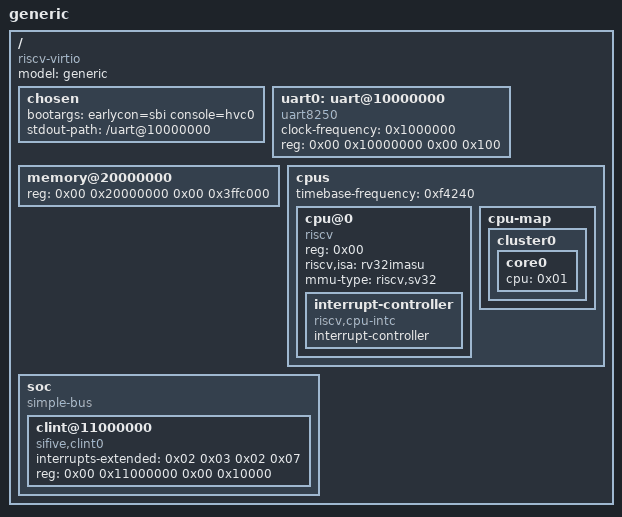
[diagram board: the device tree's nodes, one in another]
/dts-v1/;

/ {
	#address-cells = <0x2>;
	#size-cells = <0x2>;
	compatible = "riscv-virtio";
	model = "generic";

	chosen {
			bootargs = "earlycon=sbi console=hvc0";
			stdout-path = "/uart@10000000";
	};

	uart0: uart@10000000 {
		clock-frequency = <0x1000000>;
		reg = <0x00 0x10000000 0x00 0x100>;
		compatible = "uart8250";
	};

	memory@20000000 {
		device_type = "memory";
		reg = <0x00 0x20000000 0x00 0x3ffc000>;
	};

	cpus {
		#address-cells = <0x01>;
		#size-cells = <0x00>;
		timebase-frequency = <0xf4240>;

		cpu@0 {
			device_type = "cpu";
			reg = <0x00>;
			status = "okay";
			compatible = "riscv";
			riscv,isa = "rv32imasu";
			mmu-type = "riscv,sv32";

			interrupt-controller {
				#interrupt-cells = <0x01>;
				interrupt-controller;
				compatible = "riscv,cpu-intc";
				phandle = <0x02>;
			};
		};

		cpu-map {
			cluster0 {
				core0 {
					cpu = <0x01>;
				};
			};
		};
	};

	soc {
		#address-cells = <0x2>;
		#size-cells = <0x2>;
		compatible = "simple-bus";
		ranges;

		// poweroff {
		// 	value = <0x5555>;
		// 	offset = <0x00>;
		// 	regmap = <0x04>;
		// 	compatible = "syscon-poweroff";
		// };

		// reboot {
		// 	value = <0x7777>;
		// 	offset = <0x00>;
		// 	regmap = <0x04>;
		// 	compatible = "syscon-reboot";
		// };

		// syscon@11100000 {
		// 	phandle = <0x04>;
		// 	reg = <0x00 0x11100000 0x00 0x1000>;
		// 	compatible = "syscon";
		// };

		clint@11000000 {
			interrupts-extended = <0x02 0x03 0x02 0x07>;
			reg = <0x00 0x11000000 0x00 0x10000>;
			compatible = "sifive,clint0\0riscv,clint0";
		};
	};
};
